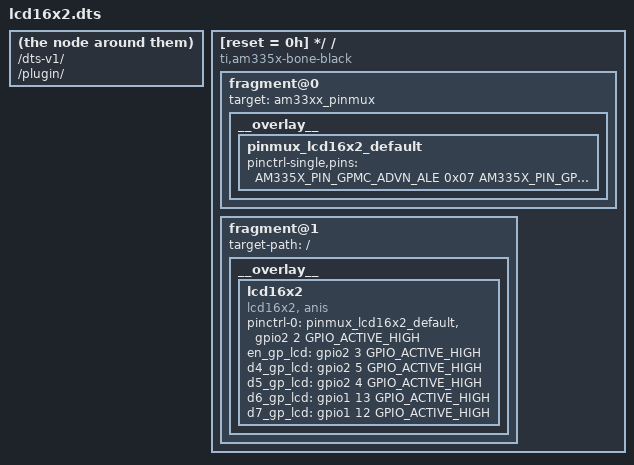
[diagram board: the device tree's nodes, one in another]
/dts-v1/;
/plugin/;

#include <linux/include/dt-bindings/pinctrl/am33xx.h> 	// Required for pad config names & AM33XX pinctrl bindings

/*	BeagleBone Black Pin_Header P8
	LCD-16x2 Pins - connected to board

	P8_Pin	ADDR	GPIO Name	Mode0-Name 		SOC-Pin		LCD-Pin
	------  ----    ---------   ----------      -------     -------
	P8_07	0x890	gpio2[2]	gpmc_advn_ale	R7			RS
	P8_08	0x894	gpio2[3]	gpmc_oen_ren	T7			EN
	P8_09	0x89c	gpio2[5]	gpmc_be0n_cle 	T6			D4
	P8_10	0x898	gpio2[4]	gpmc_wen 		U6			D5
	P8_11	0x834	gpio1[13]	gpmc_ad13 		R12			D6
	P8_12	0x830	gpio1[12]	gpmc_ad12 		T12			D7
	
	Steps to configure the pins - This part will be taken care by pinctrl-single.c driver
	------------------------------------------------------------------------------
	Pinmux Configuration = 	Control Module Registers		(address = 0x44E10000)
	------------------------------------------------------------------------------
	Set Pinmux for GPIO =  	conf_gpmc_advn_ale Register 	(offset = 890h)
							conf_gpmc_advn_ale Register		(offset = 894h)
							conf_conf_gpmc_oen_ren Register	(offset = 898h)
							conf_gpmc_be0n_cle Register		(offset = 89Ch)
							conf_gpmc_wen Register			(offset = 8A0h)
							conf_gpmc_ad13 Register			(offset = 8A4h)
							conf_gpmc_ad12 Register			(offset = 8A8h)
	
							   GPIO0 Register				(address = 0x44E07000)
	------------------------------------------------------------------------------
	/*This part will be taken care by gpiod driver*/
	Clock Enable through     = GPIO_CTRL Register 			(offset = 130h) [reset = 0h]
	Pin Direction set using  = GPIO_OE Register 			(offset = 134h) [reset = FFFFFFFFh]	
	Pin Output control using = GPIO_DATAOUT Register 		(offset = 13Ch) [reset = 0h]
							   GPIO_CLEARDATAOUT Register 	(offset = 190h) [reset = 0h]
							   GPIO_SETDATAOUT Register 	(offset = 194h) [reset = 0h]
*/

/ {
    compatible = "ti,am335x-bone-black", "ti,am335x-bone", "ti,am33xx";
	
    fragment@0 {
        target = <&am33xx_pinmux>;
        __overlay__ {
            pinmux_lcd16x2_default {
                pinctrl-single,pins = 
				<
                    AM335X_PIN_GPMC_ADVN_ALE 	0x07
                    AM335X_PIN_GPMC_OEN_REN 	0x07
                    AM335X_PIN_GPMC_WEN 		0x07
                    AM335X_PIN_GPMC_BEN0_CLE 	0x07
                    AM335X_PIN_LCD_DATA0 		0x07
                    AM335X_PIN_LCD_DATA1		0x07
                >;
            };
        };
    };

    fragment@1 {
        target-path = "/";
        __overlay__ {
            lcd16x2 {
                compatible = "lcd16x2, anis";
				pinctrl-names = "default";
				pinctrl-0 = <&pinmux_lcd16x2_default>
				rs_gp_lcd = <&gpio2 2 	GPIO_ACTIVE_HIGH>;
				en_gp_lcd = <&gpio2 3 	GPIO_ACTIVE_HIGH>;
				d4_gp_lcd = <&gpio2 5 	GPIO_ACTIVE_HIGH>;
				d5_gp_lcd = <&gpio2 4 	GPIO_ACTIVE_HIGH>;
				d6_gp_lcd = <&gpio1 13 GPIO_ACTIVE_HIGH>;
				d7_gp_lcd = <&gpio1 12 GPIO_ACTIVE_HIGH>;
			};
		};
	};
};
